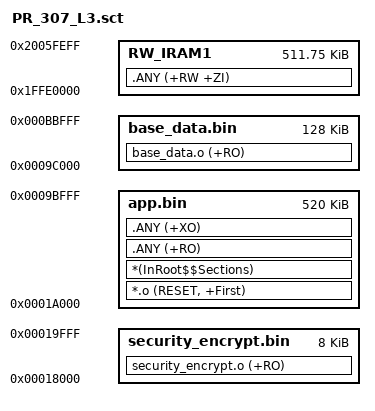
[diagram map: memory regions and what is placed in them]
; *************************************************************
; *** Scatter-Loading Description File generated by uVision ***
; *************************************************************

LR_IROM1 0x1A000 0x82000  {    ; load region size_region
	app.bin 0x1A000 0x82000  {  ; load address = execution address
		*.o (RESET, +First)
		*(InRoot$$Sections)
		.ANY (+RO)
		.ANY (+XO)
	}
	RW_IRAM1 0x1FFE0000 0x7FF00  {  ; RW data
		.ANY (+RW +ZI)
	}
}

LR_ROM1 0x18000 0x00002000  {
	security_encrypt.bin 0x18000 0x00002000 { ; load address = execution address
		security_encrypt.o (+RO)
	}
}

LR_ROM2 0x0009C000 0x00020000  {
	base_data.bin 0x0009C000 0x00020000  {  ; load address = execution address
		base_data.o (+RO)
	}
}

